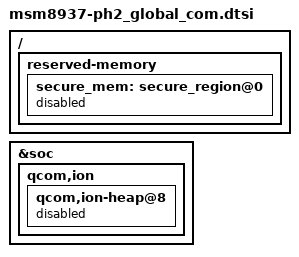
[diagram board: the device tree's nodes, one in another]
/*
 * Copyright (c) 2015, The Linux Foundation. All rights reserved.
 *
 * This program is free software; you can redistribute it and/or modify
 * it under the terms of the GNU General Public License version 2 and
 * only version 2 as published by the Free Software Foundation.
 *
 * This program is distributed in the hope that it will be useful,
 * but WITHOUT ANY WARRANTY; without even the implied warranty of
 * MERCHANTABILITY or FITNESS FOR A PARTICULAR PURPOSE.  See the
 * GNU General Public License for more details.
 */

#include "msm8937-ph2_global_com-pinctrl.dtsi"
#include "msm8937-ph2_global_com-camera.dtsi"
#include "msm8937-ph2_global_com-panel.dtsi"
#include "msm8937-ph2_global_com-sound.dtsi"
#include "msm8937-ph2_global_com-misc.dtsi"
#include "msm8937-ph2_global_com-pm.dtsi"
#include "msm8937-ph2_global_com-touch.dtsi"
#include "msm8937-ph2_global_com-nfc.dtsi"

/{
	reserved-memory {
		secure_mem: secure_region@0 {
			status = "disabled";
		};
	};
};

&soc {
	qcom,ion {
		qcom,ion-heap@8 { /* CP_MM HEAP  */
			status = "disabled";
		};
	};
};

